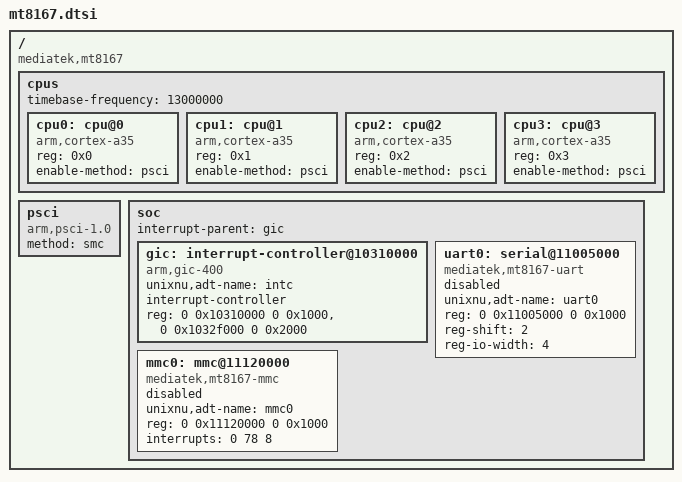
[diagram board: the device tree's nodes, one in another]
// SPDX-License-Identifier: BSD-2-Clause-Patent
// MediaTek MT8167: the resources that UniXNU exports to the ADT (devicetree.py). Addresses as in Linux
// arch/arm64/boot/dts/mediatek/mt8516.dtsi (v6.12, which mt8167.dtsi includes), checked on the Benesse TAB-A04-BR3.
/ {
    #address-cells = <2>;
    #size-cells = <2>;
    compatible = "mediatek,mt8167";

    cpus {
        #address-cells = <1>;
        #size-cells = <0>;
        // The architectural timer runs at 13 MHz (CNTFRQ_EL0 left by the firmware).
        timebase-frequency = <13000000>;

        cpu0: cpu@0 { device_type = "cpu"; compatible = "arm,cortex-a35"; reg = <0x0>; enable-method = "psci"; };
        cpu1: cpu@1 { device_type = "cpu"; compatible = "arm,cortex-a35"; reg = <0x1>; enable-method = "psci"; };
        cpu2: cpu@2 { device_type = "cpu"; compatible = "arm,cortex-a35"; reg = <0x2>; enable-method = "psci"; };
        cpu3: cpu@3 { device_type = "cpu"; compatible = "arm,cortex-a35"; reg = <0x3>; enable-method = "psci"; };
    };

    psci {
        compatible = "arm,psci-1.0";
        method = "smc";
    };

    soc {
        #address-cells = <2>;
        #size-cells = <2>;
        ranges;
        interrupt-parent = <&gic>;

        // GIC-400 (GICv2): distributor and CPU interface. Linux lists GICC at 0x10320000 with 4 KiB; the GIC-400 repeats each
        // 4 KiB CPU interface page across 64 KiB, so 0x1032f000 + 8 KiB covers both GICC pages contiguously (GICC_DIR at +0x1000).
        // ArmCpu's GICv2 path used this window on hardware.
        gic: interrupt-controller@10310000 {
            compatible = "arm,gic-400";
            unixnu,adt-name = "intc";
            #interrupt-cells = <3>;
            interrupt-controller;
            reg = <0 0x10310000 0 0x1000>, <0 0x1032f000 0 0x2000>;
        };

        // UART0: 16550 registers at 32-bit spacing; the firmware leaves it at 921600 baud.
        uart0: serial@11005000 {
            compatible = "mediatek,mt8167-uart", "mediatek,mt6577-uart", "ns16550a";
            device_type = "serial";
            unixnu,adt-name = "uart0";
            reg = <0 0x11005000 0 0x1000>;
            reg-shift = <2>;
            reg-io-width = <4>;
            status = "disabled";
        };

        // MSDC0 (eMMC).
        mmc0: mmc@11120000 {
            compatible = "mediatek,mt8167-mmc";
            unixnu,adt-name = "mmc0";
            reg = <0 0x11120000 0 0x1000>;
            interrupts = <0 78 8>;   // GIC_SPI 78 IRQ_TYPE_LEVEL_LOW
            status = "disabled";
        };
    };
};
